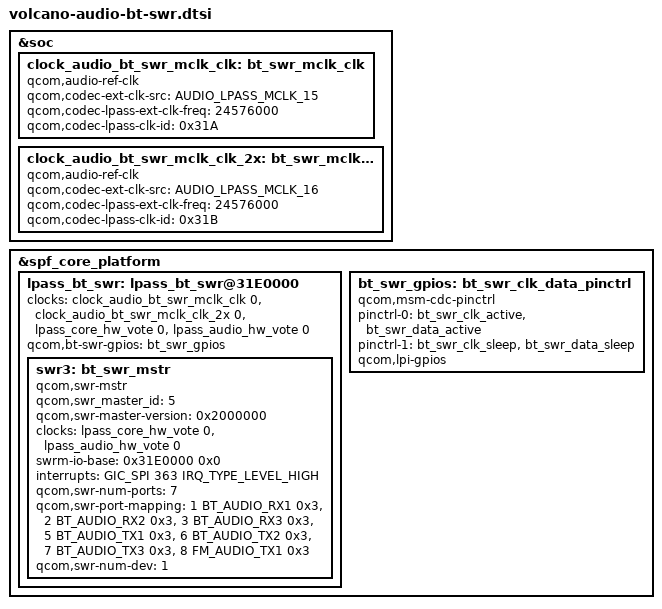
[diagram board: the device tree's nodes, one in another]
&soc {
	clock_audio_bt_swr_mclk_clk: bt_swr_mclk_clk {
		compatible = "qcom,audio-ref-clk";
		qcom,codec-ext-clk-src = <AUDIO_LPASS_MCLK_15>;
		qcom,codec-lpass-ext-clk-freq = <24576000>;
		qcom,codec-lpass-clk-id = <0x31A>;
		#clock-cells = <1>;
	};

	clock_audio_bt_swr_mclk_clk_2x: bt_swr_mclk_clk_2x {
		compatible = "qcom,audio-ref-clk";
		qcom,codec-ext-clk-src = <AUDIO_LPASS_MCLK_16>;
		qcom,codec-lpass-ext-clk-freq = <24576000>;
		qcom,codec-lpass-clk-id = <0x31B>;
		#clock-cells = <1>;
	};
};

&spf_core_platform  {
	lpass_bt_swr: lpass_bt_swr@31E0000 {
		clock-names = "bt_swr_mclk_clk", "bt_swr_mclk_clk_2x",
			"lpass_core_hw_vote", "lpass_audio_hw_vote";
		clocks = <&clock_audio_bt_swr_mclk_clk 0>, <&clock_audio_bt_swr_mclk_clk_2x 0>,
			<&lpass_core_hw_vote 0>, <&lpass_audio_hw_vote 0>;
		qcom,bt-swr-gpios = <&bt_swr_gpios>;

		swr3: bt_swr_mstr {
			compatible = "qcom,swr-mstr";
			qcom,swr_master_id = <5>;
			qcom,swr-master-version = <0x2000000>;
			clock-names = "lpass_core_hw_vote",
				"lpass_audio_hw_vote";
			clocks = <&lpass_core_hw_vote 0>,
				<&lpass_audio_hw_vote 0>;
			swrm-io-base = <0x31E0000 0x0>;
			interrupts = <GIC_SPI 363 IRQ_TYPE_LEVEL_HIGH>;
			interrupt-names = "swr_master_irq";
			qcom,swr-num-ports = <7>;
			qcom,swr-port-mapping = <1 BT_AUDIO_RX1 0x3>,
				<2 BT_AUDIO_RX2 0x3>, <3 BT_AUDIO_RX3 0x3>,
				<5 BT_AUDIO_TX1 0x3>, <6 BT_AUDIO_TX2 0x3>,
				<7 BT_AUDIO_TX3 0x3>, <8 FM_AUDIO_TX1 0x3>;
			qcom,swr-num-dev = <1>;
		};
	};

	bt_swr_gpios: bt_swr_clk_data_pinctrl {
		compatible = "qcom,msm-cdc-pinctrl";
		pinctrl-names = "aud_active", "aud_sleep";
		pinctrl-0 = <&bt_swr_clk_active &bt_swr_data_active>;
		pinctrl-1 = <&bt_swr_clk_sleep &bt_swr_data_sleep>;
		qcom,lpi-gpios;
		#gpio-cells = <0>;
	};
};
